# REGS register map
File version: 1.0
Registers are 32-bit, access not given, no defined reset value unless marked. A register's access mark holds for its fields unless they carry their own. Offsets are from the block's base; lines under a group give offsets from that group; [hi:lo] are bit positions; {n}, {i} and the like mark numbered series; 'fields as' and 'values as' point back to an identical list; <NAME> marks a mode.

## Memory map
0x40000000 MODES — Modes stated by the register, inherited from the peripheral, and taken from the fields.
0x40001000 FROM_FIELDS — No element states an access: the mode comes from the fields.
0x40002000 SIZES

## MODES — Modes stated by the register, inherited from the peripheral, and taken from the fields.
Base 0x40000000
0x00 STATED_WO wo — States write-only over its peripheral's read-only.
0x04 STATED_RW rw
0x08 INHERITED ro — Takes read-only from the peripheral.

## FROM_FIELDS — No element states an access: the mode comes from the fields.
Base 0x40001000
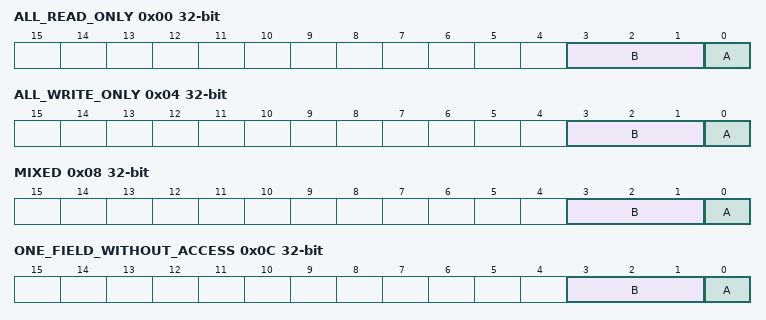
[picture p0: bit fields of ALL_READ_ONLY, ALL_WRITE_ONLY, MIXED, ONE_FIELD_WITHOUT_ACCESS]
0x00 ALL_READ_ONLY ro
  [3:1] B, [0] A
0x04 ALL_WRITE_ONLY wo
  [3:1] B, [0] A
0x08 MIXED access per field — One read-only field and one write-only field.
  [3:1] B wo, [0] A ro
0x0C ONE_FIELD_WITHOUT_ACCESS
  [3:1] B, [0] A ro
0x10 NO_FIELDS — With no field, read write.

## SIZES
Base 0x40002000
0x00 R8 8-bit
0x02 R16 16-bit
0x04 R32 — Takes the device's 32 bits.
0x08 R64 64-bit — 64 bits: left out and warned.
0x10 RESET_ZERO reset 0x0
0x14 RESET_NONZERO reset 0x12 — A reset value, and no field to give a default: warned.
